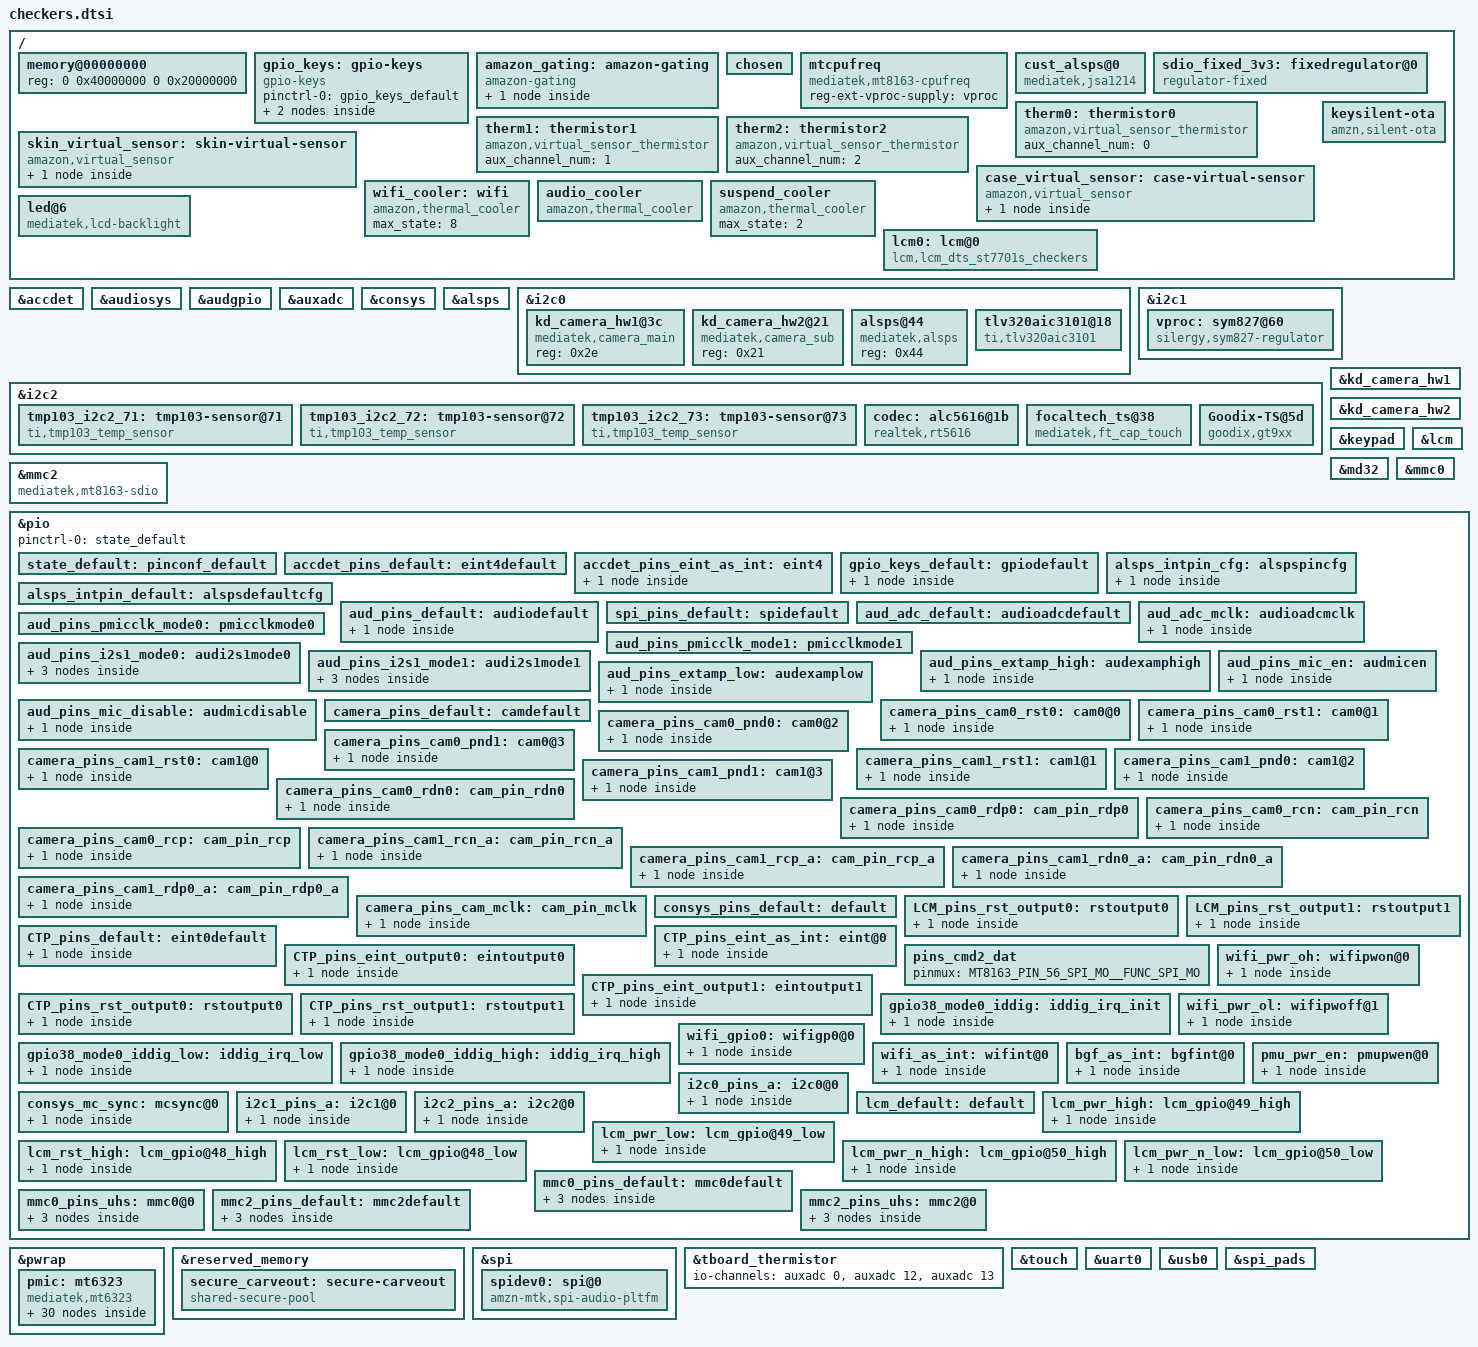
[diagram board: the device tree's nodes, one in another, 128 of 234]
/*
 * Copyright (C) 2018 Amazon.com
 *
 * This program is free software: you can redistribute it and/or modify
 * it under the terms of the GNU General Public License version 2 as
 * published by the Free Software Foundation.
 *
 * This program is distributed in the hope that it will be useful,
 * but WITHOUT ANY WARRANTY; without even the implied warranty of
 * MERCHANTABILITY or FITNESS FOR A PARTICULAR PURPOSE. See the
 * GNU General Public License for more details.
 *
 */

#include "mt8163.dtsi"
#include <dt-bindings/gpio/gpio.h>

/ {
	memory@00000000 {
		device_type = "memory";
		reg = <0 0x40000000 0 0x20000000>;
	};

	gpio_keys: gpio-keys {
		compatible = "gpio-keys";
		pinctrl-names = "default";
		pinctrl-0 = <&gpio_keys_default>;

		button@0 {
			debounce_interval = <50>;
			wakeup-source;
			gpio-key,wakeup = <1>;
			gpios = <&pio 36 1>;
			label = "volumeup";
			linux,input-type = <0x1>;
			linux,code = <115>;
		};

		button@1 {
			debounce_interval = <50>;
			wakeup-source;
			gpio-key,wakeup = <1>;
			gpios = <&pio 37 1>;
			label = "volumedown";
			linux,input-type = <0x1>;
			linux,code = <114>;
		};
	};

	amazon_gating: amazon-gating {
		compatible = "amazon-gating";
		state-gpios = <&pio 48 GPIO_ACTIVE_LOW>;
		enable-gpios = <&pio 27 GPIO_ACTIVE_HIGH>;
		status="okay";

		input_event {
			label = "mute";
			linux,code = <116>;
			debounce-interval = <50>;
			wakeup-source;
			gpios = <&pio 47 GPIO_ACTIVE_HIGH>;
		};
	};

	chosen {
		bootargs = "console=ttyMT0,921600n1 root=/dev/ram initrd=0x44000200,0x200000";
	};

	mtcpufreq {
		compatible = "mediatek,mt8163-cpufreq";
		reg-ext-vproc-supply = <&vproc>;
	};

	cust_alsps@0 {
		compatible = "mediatek,jsa1214";
		i2c_num = <0>;
		i2c_addr = <0x44>;
		polling_mode_ps = <0>;
		polling_mode_als = <1>;
		power_id = <0xffff>;
		power_vol  = <0>;
		als_level = <0 257 637 1027 2297 5588 6730 11301 20449 25768 31122 45552 57937 57937 57937>;
		als_value = <0 132 304 502 1004 2003 3006 5006 8004 10000 12000 16000 20000 20000 20000 20000>;
		ps_threshold_high = <70>;
		ps_threshold_low = <40>;
		is_batch_supported_ps = <1>;
	};

	sdio_fixed_3v3: fixedregulator@0 {
		compatible = "regulator-fixed";
		regulator-name = "sdio_fixed_3v3";
		regulator-min-microvolt = <3300000>;
		regulator-max-microvolt = <3300000>;
		gpio = <&pio 32 GPIO_ACTIVE_HIGH>;
		enable-active-high;
		startup-delay-us = <500000>;
	};

	therm0: thermistor0 {
		compatible = "amazon,virtual_sensor_thermistor";
		#thermal-sensor-cells = <0>;
		aux_channel_num = <0>;
	};
	therm1: thermistor1 {
		compatible = "amazon,virtual_sensor_thermistor";
		#thermal-sensor-cells = <0>;
		aux_channel_num = <1>;
	};
	therm2: thermistor2 {
		compatible = "amazon,virtual_sensor_thermistor";
		#thermal-sensor-cells = <0>;
		aux_channel_num = <2>;
	};

	skin_virtual_sensor: skin-virtual-sensor {
		compatible = "amazon,virtual_sensor";
		#thermal-sensor-cells = <0>;

		zone-list {
			zone-names = "therm0_s", "therm1_s", "therm2_s", "mtktscpu";
			therm0_s = <0 10000 100 550 (-40000) 125000>;
			therm1_s = <0 26949 100 100 (-40000) 125000>;
			therm2_s = <0 0 0 0 (-40000) 125000>;
			mtktscpu = <0 0 0 0 0 0>;
		};
	};

	case_virtual_sensor: case-virtual-sensor {
		compatible = "amazon,virtual_sensor";
		#thermal-sensor-cells = <0>;

		zone-list {
			zone-names = "therm0_s", "therm1_s", "therm2_s", "mtktscpu";
			therm0_s = <0 0 0 0 (-40000) 125000>;
			therm1_s = <0 0 0 0 (-40000) 125000>;
			therm2_s = <0 0 0 0 (-40000) 125000>;
			mtktscpu = <0 0 100 1000 0 0>;
		};
	};

	wifi_cooler: wifi {
		compatible = "amazon,thermal_cooler";
		#cooling-cells = <2>;
		max_state = <8>;
	};

	audio_cooler: audio_cooler {
		compatible = "amazon,thermal_cooler";
		#cooling-cells = <2>;
		max_level = <3>;
		max_state = <8>;
	};

	suspend_cooler: suspend_cooler {
		compatible = "amazon,thermal_cooler";
		#cooling-cells = <2>;
		max_state = <2>;
	};

	led@6 {
		compatible = "mediatek,lcd-backlight";
		led_mode = <5>;
		data = < >;
		pwm_config = <0 0 0 0 0>;
		gpios = <&pio 59 0>;
	};

	lcm0: lcm@0{
		compatible = "lcm,lcm_dts_st7701s_checkers";
		pinctrl-names = "default";
		lcm_auxadc_channel = <0>;
		lcm_reset_gpio = <&pio 83 0>;
		lcm-vio-supply = <&mt6323_vgp3_reg>;
		lcm-vgp-supply = <&mt6323_vio28_reg>;
		status = "okay";
	};

	keysilent-ota {
		compatible = "amzn,silent-ota";
		keys_down = "KEY_POWER";
		keys_down_delay = <0>;
		status = "okay";
	};
};

&accdet {
	interrupt-parent = <&pio>;
	interrupts = <4 IRQ_TYPE_LEVEL_LOW>;
	eint-debounce = <256000>;
	accdet-gpio = <&pio 26 0>;
	mic_dangling_vol = <1650>;
	mic_voltage_delay = <80>;
	switch-mode-vol = <550>;
	switch-mode-delay = <500>;
	accdet-mic-vol = <7>;
	headset-mode-setting = <0x500 0x500 1 0x1f0 0x800 0x800 0x4000>;
	accdet-plugout-debounce = <1000>;
	accdet-mic-mode = <1>;
	accdet-micbias1-ind-ctl = <1>;
	headset-three-key-threshold = <0 100 220 500>;
	headset-four-key-threshold = <0 58 121 192 450>;
	pinctrl-names = "default", "state_eint_as_int";
	pinctrl-0 = <&accdet_pins_default>;
	pinctrl-1 = <&accdet_pins_eint_as_int>;
	status = "okay";
};

&audiosys {
	/*0:Stereo, 1:MonoLeft, 2:MonoRight*/
	channel-type = <0>;
	switch-mode-delay = <1>;
	sound-dai = <&codec>;
	/* MCLK Frequency for ADC/DAC */
	mclk-frequency = <24576000>;
	/* enable mic callback for gating mode */
	gating_mode_callback_en = <1>;
	/* enable mclk source for DAC clock, 0 for Bclk */
	use_mclk_source_en = <0>;
};

&audgpio {
	pinctrl-names = "default",
			"audpmicclk-mode0",
			"audpmicclk-mode1",
			"audi2s1-mode0",
			"audi2s1-mode1",
			"extamp-pullhigh",
			"extamp-pulllow",
			"i2s-mclk",
			"mic-enable",
			"mic-disable";
	pinctrl-0 = <&aud_pins_default>;
	pinctrl-1 = <&aud_pins_pmicclk_mode0>;
	pinctrl-2 = <&aud_pins_pmicclk_mode1>;
	pinctrl-3 = <&aud_pins_i2s1_mode0>;
	pinctrl-4 = <&aud_pins_i2s1_mode1>;
	pinctrl-5 = <&aud_pins_extamp_high>;
	pinctrl-6 = <&aud_pins_extamp_low>;
	pinctrl-7 = <&aud_adc_mclk>;
	pinctrl-8 = <&aud_pins_mic_en>;
	pinctrl-9 = <&aud_pins_mic_disable>;

	clocks = <&infracfg CLK_INFRA_AUDIO>,
			<&topckgen CLK_TOP_AUDIO_SEL>,
			<&topckgen CLK_TOP_AUD_INTBUS_SEL>,
			<&topckgen CLK_TOP_AUD_1_SEL>,
			<&topckgen CLK_TOP_AUD_2_SEL>,
			<&topckgen CLK_TOP_APLL1>,
			<&topckgen CLK_TOP_APLL2>,
			<&audiosys CLK_AUDIO_AFE>,
			<&audiosys CLK_AUDIO_DAC>,
			<&audiosys CLK_AUDIO_DAC_PREDIS>,
			<&audiosys CLK_AUDIO_ADC>,
			<&audiosys CLK_AUDIO_22M>,
			<&audiosys CLK_AUDIO_24M>,
			<&audiosys CLK_AUDIO_I2S>,
			<&audiosys CLK_AUDIO_APLL_TUNER>,
			<&audiosys CLK_AUDIO_APLL2_TUNER>,
			<&clk26m>;

	clock-names = "aud_infra_clk",
			"top_mux_audio",
			"top_mux_audio_intbus",
			"aud_mux1_clk",
			"aud_mux2_clk",
			"apll1_clk",
			"apll2_clk",
			"aud_afe",
			"aud_dac",
			"aud_dac_predis",
			"aud_adc",
			"aud_22m",
			"aud_24m",
			"aud_i2s",
			"aud_apll_tnr",
			"aud_apll2_tnr",
			"top_clk26m_clk";

	status = "okay";
};

&auxadc {
	status = "okay";
};

&consys {
	pinctrl-names = "default",
			"wifi_pwr_on",
			"wifi_pwr_off",
			"wifi_gpio0",
			"wifi_int",
			"bgf_int",
			"pmu_pw_en",
			"mc_sync";
	pinctrl-0 = <&consys_pins_default>;
	pinctrl-1 = <&wifi_pwr_oh>;
	pinctrl-2 = <&wifi_pwr_ol>;
	pinctrl-3 = <&wifi_gpio0>;
	pinctrl-4 = <&wifi_as_int>;
	pinctrl-5 = <&bgf_as_int>;
	pinctrl-6 = <&pmu_pwr_en>;
	pinctrl-7 = <&consys_mc_sync>;
	vio18-supply = <&mt6323_vio18_reg>;
	status = "okay";
};

&alsps {
	pinctrl-names = "pin_default", "pin_cfg";
	pinctrl-0 = <&alsps_intpin_default>;
	pinctrl-1 = <&alsps_intpin_cfg>;
	vcn28-supply = <&mt6323_vcn28_reg>;
	status = "okay";
};

&i2c0 {
	clock-frequency = <400000>;
	pinctrl-names = "default";
	pinctrl-0 = <&i2c0_pins_a>;
	status = "okay";

	kd_camera_hw1@3c {
		compatible = "mediatek,camera_main";
		reg = <0x2e>;
	};

	kd_camera_hw2@21 {
		compatible = "mediatek,camera_sub";
		reg = <0x21>;
	};

	alsps@44 {
		compatible = "mediatek,alsps";
		reg = <0x44>;
		status = "okay";
	};

	tlv320aic3101@18 {
		compatible = "ti,tlv320aic3101";
		reg = <0x18>;
		enable-gpio = <&pio 24 0>;
		clocks = <&clk26m>;
		clock-names = "mclk";
	};
};

&i2c1 {
	clock-frequency = <400000>;
	pinctrl-names = "default";
	pinctrl-0 = <&i2c1_pins_a>;
	status = "okay";

	vproc: sym827@60 {
		compatible = "silergy,sym827-regulator";
		reg = <0x60>;
		regulator-name = "vproc";
		regulator-min-microvolt = <600000>;
		regulator-max-microvolt = <1387500>;
		regulator-enable-ramp-delay = <400>;
		regulator-ramp-delay = <8333>;
		regulator-always-on;
		vsel-gpio = <&pio 34 0>;
	};
};

&i2c2 {
	clock-frequency = <400000>;
	pinctrl-names = "default";
	pinctrl-0 = <&i2c2_pins_a>;
	status = "okay";

	tmp103_i2c2_71: tmp103-sensor@71 {
		compatible = "ti,tmp103_temp_sensor";
		reg = <0x71>;
		tmp103-sensor,offset = <2300>;
		tmp103-sensor,alpha = <10>;
		tmp103-sensor,weight = <0>;
	};
	tmp103_i2c2_72: tmp103-sensor@72 {
		compatible = "ti,tmp103_temp_sensor";
		reg = <0x72>;
		tmp103-sensor,offset = <750>;
		tmp103-sensor,alpha = <10>;
		tmp103-sensor,weight = <0>;
	};
	tmp103_i2c2_73: tmp103-sensor@73 {
		compatible = "ti,tmp103_temp_sensor";
		reg = <0x73>;
		tmp103-sensor,offset = <750>;
		tmp103-sensor,alpha = <10>;
		tmp103-sensor,weight = <0>;
	};

	codec: alc5616@1b {
		compatible = "realtek,rt5616";
		reg = <0x1b>;
		/* hw_mode=1 for differential 0 for Single_end*/
		hw_mode= <1>;
		/* Checkers Buzz and Pop SW solution */
		depop_mode= <1>;
		realtek,amp-gpio = <&pio 35 0>;
		pinctrl-names = "default",
				"adc-mclk";
		pinctrl-0 = <&aud_adc_default>;
		pinctrl-1 = <&aud_adc_mclk>;
	};

	focaltech_ts@38{
		compatible = "mediatek,ft_cap_touch";
		reg = <0x38>;
		vdd-supply = <&mt6323_vmch_reg>;
		vccio-supply = <&mt6323_vio18_reg>;
		focaltech,rst-gpio = <&pio 123 0x00>;
		focaltech,irq-gpio = <&pio 122 0x00>;
		focaltech,display-data = <0 480 0 960>;
		focaltech,fts-key-number = <5>;
	};

	Goodix-TS@5d{
		compatible = "goodix,gt9xx";
		reg = <0x5d>;
		goodix,rst-gpio = <&pio 123 0x00>;
		goodix,irq-gpio = <&pio 122 0x00>;
		vdd_ana-supply = <&mt6323_vmch_reg>;
		/* for now, we'd better not control VIO18 as it is shared by other circuits */
		/* vcc_i2c-supply = <&mt6323_vio18_reg>; */
		/* KD module config */
		goodix,cfg-group0 = [
		51 E0 01 C0 03 05 35 08 01 08
		23 05 50 32 25 03 00 00 00 00
		22 02 30 14 1B 1F 14 8C EC 0C
		50 52 7C 06 46 41 61 BB 02 10
		00 00 00 00 00 00 00 00 00 00
		00 3C 58 8F E0 65 14 0A 00 04
		9A 3E 00 91 43 00 8A 48 00 82
		4E 00 7B 54 00 7B 00 00 00 00
		01 1E 14 00 00 00 00 50 7C 06
		1E 00 00 00 00 00 00 00 00 00
		00 00 00 00 00 00 00 00 00 00
		00 00 18 16 14 12 10 0E 0C 0A
		08 06 04 02 FF FF FF FF FF FF
		FF FF FF FF FF FF FF FF FF FF
		FF FF 00 02 04 06 08 0A 0C 0F
		10 12 13 14 16 18 1C 1D 1E 1F
		20 21 22 24 26 28 FF FF FF FF
		FF FF FF FF FF FF FF FF FF FF
		FF FF FF FF 23 01];
		/* TRULY module config */
		goodix,cfg-group1 = [
		51 E0 01 C0 03 05 35 08 01 08
		23 05 50 32 25 03 00 00 00 00
		22 02 30 14 1B 1F 14 8C EC 0C
		50 52 7C 06 46 41 61 BB 02 10
		00 00 00 00 00 00 00 00 00 00
		00 3C 58 8F E0 65 14 0A 00 04
		9A 3E 00 91 43 00 8A 48 00 82
		4E 00 7B 54 00 7B 00 00 00 00
		01 1E 14 00 00 00 00 50 7C 06
		1E 00 00 00 00 00 00 00 00 00
		00 00 00 00 00 00 00 00 00 00
		00 00 18 16 14 12 10 0E 0C 0A
		08 06 04 02 FF FF FF FF FF FF
		FF FF FF FF FF FF FF FF FF FF
		FF FF 00 02 04 06 08 0A 0C 0F
		10 12 13 14 16 18 1C 1D 1E 1F
		20 21 22 24 26 28 FF FF FF FF
		FF FF FF FF FF FF FF FF FF FF
		FF FF FF FF 23 01];
		/* INX module config */
		goodix,cfg-group2 = [
		51 E0 01 C0 03 05 35 08 01 08
		23 05 50 32 25 03 00 00 00 00
		22 02 30 14 1B 1F 14 8C EC 0C
		50 52 7C 06 46 41 61 BB 02 10
		00 00 00 00 00 00 00 00 00 00
		00 3C 58 8F E0 65 14 0A 00 04
		9A 3E 00 91 43 00 8A 48 00 82
		4E 00 7B 54 00 7B 00 00 00 00
		01 1E 14 00 00 00 00 50 7C 06
		1E 00 00 00 00 00 00 00 00 00
		00 00 00 00 00 00 00 00 00 00
		00 00 18 16 14 12 10 0E 0C 0A
		08 06 04 02 FF FF FF FF FF FF
		FF FF FF FF FF FF FF FF FF FF
		FF FF 00 02 04 06 08 0A 0C 0F
		10 13 12 14 16 18 1C 1D 1E 1F
		20 26 28 21 22 24 FF FF FF FF
		FF FF FF FF FF FF FF FF FF FF
		FF FF FF FF 23 01];
		/* KD_WALLY module config */
		goodix,cfg-group3 = [
		51 E0 01 C0 03 05 35 08 01 08
		23 05 50 32 25 03 00 00 00 00
		22 02 30 14 1B 1F 14 8C EC 0C
		50 52 7C 06 46 41 61 BB 02 10
		00 00 00 00 00 00 00 00 00 00
		00 3C 58 8F E0 65 14 0A 00 04
		9A 3E 00 91 43 00 8A 48 00 82
		4E 00 7B 54 00 7B 00 00 00 00
		01 1E 14 00 00 00 00 50 7C 06
		1E 00 00 00 00 00 00 00 00 00
		00 00 00 00 00 00 00 00 00 00
		00 00 18 16 14 12 10 0E 0C 0A
		08 06 04 02 FF FF FF FF FF FF
		FF FF FF FF FF FF FF FF FF FF
		FF FF 00 02 04 06 08 0A 0C 0F
		10 12 13 14 16 18 1C 1D 1E 1F
		20 21 22 24 26 28 FF FF FF FF
		FF FF FF FF FF FF FF FF FF FF
		FF FF FF FF 23 01];
		status = "okay";
	};
};

/* Main Cam */
&kd_camera_hw1 {

	reg-vcama-supply = <&mt6323_vcama_reg>;
	reg-vcamd-supply = <&mt6323_vgp1_reg>;
	reg-vcamio-supply = <&mt6323_vcamio_reg>;
	reg-vcami2c-supply = <&mt6323_vio18_reg>;	/*I2C*/

	pinctrl-names = "default", "cam_mclk",
		"cam0_rst0", "cam0_rst1", "cam0_pnd0", "cam0_pnd1",
		"cam0_rdn0", "cam0_rdp0", "cam0_rcn", "cam0_rcp";
	pinctrl-0 = <&camera_pins_default>;
	pinctrl-1 = <&camera_pins_cam_mclk>;
	pinctrl-2 = <&camera_pins_cam0_rst0>;
	pinctrl-3 = <&camera_pins_cam0_rst1>;
	pinctrl-4 = <&camera_pins_cam0_pnd0>;
	pinctrl-5 = <&camera_pins_cam0_pnd1>;
	pinctrl-6 = <&camera_pins_cam0_rdn0>;
	pinctrl-7 = <&camera_pins_cam0_rdp0>;
	pinctrl-8 = <&camera_pins_cam0_rcn>;
	pinctrl-9 = <&camera_pins_cam0_rcp>;
	status = "okay";

};

/* Sub Cam */
/* FIX ME: same power pins as Main ? */
&kd_camera_hw2 {
	reg-vcama-supply = <&mt6323_vcama_reg>;
	reg-vcamd-supply = <&mt6323_vgp1_reg>;
	reg-vcamio-supply = <&mt6323_vcamio_reg>;
	reg-vcami2c-supply = <&mt6323_vio18_reg>;	/*I2C*/
};

&keypad {
};

&lcm {
	pinctrl-names = "default";
	lcm_reset_gpio = <&pio 83 0>;
	reg-lcm-supply = <&mt6323_vgp3_reg>;
	reg-lcm-supply1 = <&mt6323_vio28_reg>;
};

&md32 {
	status = "okay";
};

&mmc0 {
	pinctrl-names = "default", "state_uhs";
	pinctrl-0 = <&mmc0_pins_default>;
	pinctrl-1 = <&mmc0_pins_uhs>;
	status = "okay";
	bus-width = <8>;
	mediatek,latch-ck = <1>;
	max-frequency = <200000000>;
	/*cap-mmc-highspeed;*/
	mmc-hs200-1_8v;
	cap-mmc-hw-reset;
	vmmc-supply = <&mt6323_vemc3v3_reg>;
	vqmmc-supply = <&mt6323_vio18_reg>;
	non-removable;
};

&mmc2 {
	compatible = "mediatek,mt8163-sdio";
	pinctrl-names = "default", "state_uhs";
	pinctrl-0 = <&mmc2_pins_default>;
	pinctrl-1 = <&mmc2_pins_uhs>;
	status = "okay";
	bus-width = <4>;
	max-frequency = <200000000>;
	sd-uhs-sdr104;
	cap-sd-highspeed;
	keep-power-in-suspend;
	enable-sdio-wakeup;
	vmmc-supply = <&sdio_fixed_3v3>;
	cap-sdio-irq;
	non-removable;
	mt76x8_pmu_en_gpio = <&pio 32 0>;
	mt76x8_pmu_en_delay = <5>; /* ms */
};

&pio {
	pinctrl-names = "default";
	pinctrl-0 = <&state_default>;

	state_default:pinconf_default {
	};

	accdet_pins_default: eint4default {
	};

	accdet_pins_eint_as_int: eint4 {
		pins_cmd_dat {
			pinmux = <MT8163_PIN_26_EINT4__FUNC_GPIO26>;
			bias-disable;
		};
	};

	gpio_keys_default: gpiodefault {
		pins_cmd_dat {
			pinmux = <MT8163_PIN_36_KPCOL0__FUNC_GPIO36>,
			<MT8163_PIN_37_KPCOL1__FUNC_GPIO37>;
			slew-rate = <0>;
			bias-pull-up = <MTK_PUPD_SET_R1R0_01>;
			input-enable;
		};
	};

	alsps_intpin_cfg: alspspincfg {
		pins_cmd_dat {
			pinmux = <MT8163_PIN_52_EINT20__FUNC_GPIO52>;
			slew-rate = <0>;
			bias-pull-up = <00>;
		};
	};

	alsps_intpin_default: alspsdefaultcfg {
	};

	aud_pins_default: audiodefault {
		pins1 {
			pinmux = <MT8163_PIN_18_PCM_CLK__FUNC_I2S0_BCK0>,
				<MT8163_PIN_19_PCM_SYNC__FUNC_I2S0_LRCK>,
				<MT8163_PIN_20_PCM_RX__FUNC_I2S0_DI>,
				<MT8163_PIN_21_PCM_TX__FUNC_I2S3_DO>;
		};
	};

	spi_pins_default: spidefault {
	};

	aud_adc_default: audioadcdefault {
	};

	aud_adc_mclk: audioadcmclk {
		pins_cmd_dat {
			pinmux = <MT8163_PIN_6_PWRAP_SPI0_CSN2__FUNC_I2S1_MCK>;
		};
	};

	aud_pins_pmicclk_mode0: pmicclkmode0 {
	};

	aud_pins_pmicclk_mode1: pmicclkmode1 {
	};

	aud_pins_i2s1_mode0: audi2s1mode0 {
		pins_cmd0_dat {
			pinmux = <MT8163_PIN_72_I2S_DATA_IN__FUNC_GPIO72>;
		};
		pins_cmd1_dat {
			pinmux = <MT8163_PIN_73_I2S_LRCK__FUNC_GPIO73>;
		};
		pins_cmd2_dat {
			pinmux = <MT8163_PIN_74_I2S_BCK__FUNC_GPIO74>;
		};
	};

	aud_pins_i2s1_mode1: audi2s1mode1 {
		pins_cmd0_dat {
			pinmux = <MT8163_PIN_72_I2S_DATA_IN__FUNC_I2S1_DO>;
			drive-strength = <MTK_DRIVE_8mA>;
		};
		pins_cmd1_dat {
			pinmux = <MT8163_PIN_73_I2S_LRCK__FUNC_I2S1_LRCK>;
			drive-strength = <MTK_DRIVE_8mA>;
		};
		pins_cmd2_dat {
			pinmux = <MT8163_PIN_74_I2S_BCK__FUNC_I2S1_BCK>;
			drive-strength = <MTK_DRIVE_8mA>;
		};
	};

	aud_pins_extamp_high: audexamphigh {
		pins_cmd_dat {
			pinmux = <MT8163_PIN_35_KPROW2__FUNC_GPIO35>;
			slew-rate = <1>;
			output-high;
		};
	};

	aud_pins_extamp_low: audexamplow {
		pins_cmd_dat {
			pinmux = <MT8163_PIN_35_KPROW2__FUNC_GPIO35>;
			slew-rate = <1>;
			output-low;
		};
	};

	aud_pins_mic_en: audmicen {
		pins_cmd0_dat {
			pinmux = <MT8163_PIN_46_EINT14__FUNC_GPIO46>;
			slew-rate = <1>;
			output-high;
		};
	};

	aud_pins_mic_disable: audmicdisable {
		pins_cmd0_dat {
			pinmux = <MT8163_PIN_46_EINT14__FUNC_GPIO46>;
			slew-rate = <1>;
			output-low;
		};
	};

	camera_pins_default: camdefault {
	};

	camera_pins_cam0_rst0: cam0@0 {
		pins_cmd_dat {
			pinmux = <MT8163_PIN_22_EINT0__FUNC_GPIO22>;/* GPIO_CAMERA_CMRST_PIN */
			slew-rate = <1>; /* direction 0:in, 1:out */
			output-low;/* direction out used only. output_low or high */
		};
	};

	camera_pins_cam0_rst1: cam0@1 {
		pins_cmd_dat {
			pinmux = <MT8163_PIN_22_EINT0__FUNC_GPIO22>;/* GPIO_CAMERA_CMRST_PIN */
			slew-rate = <1>;
			output-high;
		};
	};

	camera_pins_cam0_pnd0: cam0@2 {
		pins_cmd_dat {
			pinmux = <MT8163_PIN_23_EINT1__FUNC_GPIO23>;/* GPIO_CAMERA_CMPDN_PIN */
			slew-rate = <1>;
			output-low;
		};
	};

	camera_pins_cam0_pnd1: cam0@3 {
		pins_cmd_dat {
			pinmux = <MT8163_PIN_23_EINT1__FUNC_GPIO23>;/* GPIO_CAMERA_CMPDN_PIN */
			slew-rate = <1>;
			output-high;
		};
	};

	camera_pins_cam1_rst0: cam1@0 {
		pins_cmd_dat {
			pinmux = <MT8163_PIN_22_EINT0__FUNC_GPIO22>;/* GPIO_CAMERA_CMRST1_PIN */
			slew-rate = <1>; /* direction 0:in, 1:out */
			output-low;/* direction out used only. output_low or high */
		};
	};

	camera_pins_cam1_rst1: cam1@1 {
		pins_cmd_dat {
			pinmux = <MT8163_PIN_22_EINT0__FUNC_GPIO22>;/* GPIO_CAMERA_CMRST1_PIN */
			slew-rate = <1>;
			output-high;
		};
	};

	camera_pins_cam1_pnd0: cam1@2 {
		pins_cmd_dat {
			pinmux = <MT8163_PIN_23_EINT1__FUNC_GPIO23>;/* GPIO_CAMERA_CMPDN1_PIN */
			slew-rate = <1>;
			output-low;
		};
	};

	camera_pins_cam1_pnd1: cam1@3 {
		pins_cmd_dat {
			pinmux = <MT8163_PIN_23_EINT1__FUNC_GPIO23>;/* GPIO_CAMERA_CMPDN1_PIN */
			slew-rate = <1>;
			output-high;
		};
	};

	camera_pins_cam0_rdn0: cam_pin_rdn0 {
		pins_cmd_dat {
			pinmux = <MT8163_PIN_101_RDN0__FUNC_RDN0>;
		};
	};

	camera_pins_cam0_rdp0: cam_pin_rdp0 {
		pins_cmd_dat {
			pinmux = <MT8163_PIN_102_RDP0__FUNC_RDP0>;
		};
	};

	camera_pins_cam0_rcn: cam_pin_rcn {
		pins_cmd_dat {
			pinmux = <MT8163_PIN_105_RCN__FUNC_RCN>;
		};
	};

	camera_pins_cam0_rcp: cam_pin_rcp {
		pins_cmd_dat {
			pinmux = <MT8163_PIN_106_RCP__FUNC_RCP>;
		};
	};

	camera_pins_cam1_rcn_a: cam_pin_rcn_a {
		pins_cmd_dat {
			pinmux = <MT8163_PIN_111_RCN_A__FUNC_RCN_A>;
		};
	};

	camera_pins_cam1_rcp_a: cam_pin_rcp_a {
		pins_cmd_dat {
			pinmux = <MT8163_PIN_112_RCP_A__FUNC_RCP_A>;
		};
	};

	camera_pins_cam1_rdn0_a: cam_pin_rdn0_a {
		pins_cmd_dat {
			pinmux = <MT8163_PIN_115_RDN0_A__FUNC_RDN0_A>;
		};
	};

	camera_pins_cam1_rdp0_a: cam_pin_rdp0_a {
		pins_cmd_dat {
			pinmux = <MT8163_PIN_116_RDP0_A__FUNC_RDP0_A>;
		};
	};

	camera_pins_cam_mclk: cam_pin_mclk {
		pins_cmd_dat {
			pinmux = <MT8163_PIN_119_CMMCLK__FUNC_CMMCLK>;
		};
	};

	consys_pins_default: default {

	};

	LCM_pins_rst_output0: rstoutput0 {
		pins_cmd_dat {
		pinmux = <MT8163_PIN_83_LCM_RST__FUNC_GPIO83>;
			slew-rate = <1>;
			output-low;
		};
	};

	LCM_pins_rst_output1: rstoutput1 {
		pins_cmd_dat {
			pinmux = <MT8163_PIN_83_LCM_RST__FUNC_GPIO83>;
			slew-rate = <1>;
			output-high;
		};
	};

	CTP_pins_default: eint0default {
		pins_cmd_dat {
			pinmux = <MT8163_PIN_122_MSDC1_CLK__FUNC_GPIO122>;
			slew-rate = <0>;
			bias-disable;
		};
	};

	CTP_pins_eint_as_int: eint@0 {
		pins_cmd_dat {
			pinmux = <MT8163_PIN_122_MSDC1_CLK__FUNC_GPIO122>;
			slew-rate = <0>;
			bias-disable;
		};
	};

	CTP_pins_eint_output0: eintoutput0 {
		pins_cmd_dat {
			pinmux = <MT8163_PIN_122_MSDC1_CLK__FUNC_GPIO122>;
			slew-rate = <1>;
			output-low;
		};
	};
		pins_cmd2_dat {
			pinmux = <MT8163_PIN_56_SPI_MO__FUNC_SPI_MO>;
		};

	CTP_pins_eint_output1: eintoutput1 {
		pins_cmd_dat {
			pinmux = <MT8163_PIN_122_MSDC1_CLK__FUNC_GPIO122>;
			slew-rate = <1>;
			output-high;
		};
	};

	CTP_pins_rst_output0: rstoutput0 {
		pins_cmd_dat {
			pinmux = <MT8163_PIN_123_MSDC1_DAT0__FUNC_GPIO123>;
			slew-rate = <1>;
			output-low;
		};
	};

	CTP_pins_rst_output1: rstoutput1 {
		pins_cmd_dat {
			pinmux = <MT8163_PIN_123_MSDC1_DAT0__FUNC_GPIO123>;
			slew-rate = <1>;
			output-high;
		};
	};

	gpio38_mode0_iddig: iddig_irq_init {
		pins_cmd_dat {
			pinmux = <MT8163_PIN_38_KPCOL2__FUNC_GPIO38>;
			bias-pull-up;
		};
	};

	gpio38_mode0_iddig_low: iddig_irq_low {
		pins_cmd_dat {
			pinmux = <MT8163_PIN_38_KPCOL2__FUNC_GPIO38>;
			bias-pull-down;
		};
	};

	gpio38_mode0_iddig_high: iddig_irq_high {
		pins_cmd_dat {
			pinmux = <MT8163_PIN_38_KPCOL2__FUNC_GPIO38>;
			bias-pull-up;
		};
	};

	wifi_pwr_oh: wifipwon@0 {
		pins_cmd_dat {
			pinmux = <MT8163_PIN_28_EINT6__FUNC_GPIO28>;
			slew-rate = <1>;
			output-high;
		};
	};

	wifi_pwr_ol: wifipwoff@1 {
		pins_cmd_dat {
			pinmux = <MT8163_PIN_28_EINT6__FUNC_GPIO28>;
			slew-rate = <1>;
			output-low;
		};
	};

	wifi_gpio0: wifigp0@0 {
		pins_cmd_dat {
			pinmux = <MT8163_PIN_29_EINT7__FUNC_GPIO29>;
			slew-rate = <1>;
			output-low;
		};
	};

	wifi_as_int: wifint@0 {
		pins_cmd_dat {
			pinmux = <MT8163_PIN_30_EINT8__FUNC_GPIO30>;
			slew-rate = <0>;
			bias-disable;
		};
	};

	bgf_as_int: bgfint@0 {
		pins_cmd_dat {
			pinmux = <MT8163_PIN_31_EINT9__FUNC_GPIO31>;
			slew-rate = <0>;
			bias-disable;
		};
	};

	pmu_pwr_en: pmupwen@0 {
		pins_cmd_dat {
			pinmux = <MT8163_PIN_32_EINT10__FUNC_GPIO32>;
			slew-rate = <1>;
			output-low;
		};
	};

	consys_mc_sync: mcsync@0 {
		pins_cmd_dat {
			pinmux = <MT8163_PIN_33_KPROW0__FUNC_GPIO33>;
			slew-rate = <1>;
			output-low;
		};
	};

	i2c0_pins_a: i2c0@0 {
		pins1 {
			pinmux = <MT8163_PIN_75_SDA0__FUNC_SDA0_0>,
				 <MT8163_PIN_76_SCL0__FUNC_SCL0_0>;
			bias-disable;
		};
	};

	i2c1_pins_a: i2c1@0 {
		pins1 {
			pinmux = <MT8163_PIN_57_SDA1__FUNC_SDA1_0>,
				 <MT8163_PIN_58_SCL1__FUNC_SCL1_0>;
			bias-disable;
		};
	};

	i2c2_pins_a: i2c2@0 {
		pins1 {
			pinmux = <MT8163_PIN_77_SDA2__FUNC_SDA2_0>,
				 <MT8163_PIN_78_SCL2__FUNC_SCL2_0>;
			bias-disable;
		};
	};

	lcm_default: default {
	};

	lcm_pwr_high: lcm_gpio@49_high {
		pins_cmd_dat {
			pinmux = <MT8163_PIN_49_EINT17__FUNC_GPIO49>;
			slew-rate = <1>;
			output-high;
		};
	};

	lcm_pwr_low: lcm_gpio@49_low {
		pins_cmd_dat {
			pinmux = <MT8163_PIN_49_EINT17__FUNC_GPIO49>;
			slew-rate = <1>;
			output-low;
		};
	};

	lcm_rst_high: lcm_gpio@48_high {
		pins_cmd_dat {
			pinmux = <MT8163_PIN_48_EINT16__FUNC_GPIO48>;
			slew-rate = <1>;
			output-high;
		};
	};

	lcm_rst_low: lcm_gpio@48_low {
		pins_cmd_dat {
			pinmux = <MT8163_PIN_48_EINT16__FUNC_GPIO48>;
			slew-rate = <1>;
			output-low;
		};
	};

	lcm_pwr_n_high: lcm_gpio@50_high {
		pins_cmd_dat {
			pinmux = <MT8163_PIN_50_EINT18__FUNC_GPIO50>;
			bias-disable;
		};
	};

	lcm_pwr_n_low: lcm_gpio@50_low {
		pins_cmd_dat {
			pinmux = <MT8163_PIN_50_EINT18__FUNC_GPIO50>;
			bias-disable;
		};
	};

	mmc0_pins_default: mmc0default {
		pins_cmd_dat {
			pinmux = <MT8163_PIN_137_MSDC0_DAT0__FUNC_MSDC0_DAT0>,
				<MT8163_PIN_136_MSDC0_DAT1__FUNC_MSDC0_DAT1>,
				<MT8163_PIN_135_MSDC0_DAT2__FUNC_MSDC0_DAT2>,
				<MT8163_PIN_134_MSDC0_DAT3__FUNC_MSDC0_DAT3>,
				<MT8163_PIN_130_MSDC0_DAT4__FUNC_MSDC0_DAT4>,
				<MT8163_PIN_129_MSDC0_DAT5__FUNC_MSDC0_DAT5>,
				<MT8163_PIN_128_MSDC0_DAT6__FUNC_MSDC0_DAT6>,
				<MT8163_PIN_127_MSDC0_DAT7__FUNC_MSDC0_DAT7>,
				<MT8163_PIN_132_MSDC0_CMD__FUNC_MSDC0_CMD>;
			input-enable;
			bias-pull-up;
		};

		pins_clk {
			pinmux = <MT8163_PIN_133_MSDC0_CLK__FUNC_MSDC0_CLK>;
			bias-pull-down;
		};

		pins_rst {
			pinmux = <MT8163_PIN_131_MSDC0_RSTB__FUNC_MSDC0_RSTB>;
			bias-pull-up;
		};
	};

	mmc0_pins_uhs: mmc0@0{
		pins_cmd_dat {
			pinmux = <MT8163_PIN_137_MSDC0_DAT0__FUNC_MSDC0_DAT0>,
				<MT8163_PIN_136_MSDC0_DAT1__FUNC_MSDC0_DAT1>,
				<MT8163_PIN_135_MSDC0_DAT2__FUNC_MSDC0_DAT2>,
				<MT8163_PIN_134_MSDC0_DAT3__FUNC_MSDC0_DAT3>,
				<MT8163_PIN_130_MSDC0_DAT4__FUNC_MSDC0_DAT4>,
				<MT8163_PIN_129_MSDC0_DAT5__FUNC_MSDC0_DAT5>,
				<MT8163_PIN_128_MSDC0_DAT6__FUNC_MSDC0_DAT6>,
				<MT8163_PIN_127_MSDC0_DAT7__FUNC_MSDC0_DAT7>,
				<MT8163_PIN_132_MSDC0_CMD__FUNC_MSDC0_CMD>;
			input-enable;
			drive-strength = <MTK_DRIVE_6mA>;
			bias-pull-up = <MTK_PUPD_SET_R1R0_01>;
		};

		pins_clk {
			pinmux = <MT8163_PIN_133_MSDC0_CLK__FUNC_MSDC0_CLK>;
			drive-strength = <MTK_DRIVE_6mA>;
			bias-pull-down = <MTK_PUPD_SET_R1R0_01>;
		};

		pins_rst {
			pinmux = <MT8163_PIN_131_MSDC0_RSTB__FUNC_MSDC0_RSTB>;
			bias-pull-up;
		};
	};

	mmc2_pins_default: mmc2default {
		pins_cmd_dat {
			pinmux = <MT8163_PIN_87_MSDC2_DAT0__FUNC_MSDC2_DAT0>,
				<MT8163_PIN_88_MSDC2_DAT1__FUNC_MSDC2_DAT1>,
				<MT8163_PIN_89_MSDC2_DAT2__FUNC_MSDC2_DAT2>,
				<MT8163_PIN_90_MSDC2_DAT3__FUNC_MSDC2_DAT3>,
				<MT8163_PIN_85_MSDC2_CMD__FUNC_MSDC2_CMD>;
			drive-strength = <MTK_DRIVE_6mA>;
			bias-pull-up = <MTK_PUPD_SET_R1R0_01>;
		};

		pins_clk {
			pinmux = <MT8163_PIN_86_MSDC2_CLK__FUNC_MSDC2_CLK>;
			drive-strength = <MTK_DRIVE_6mA>;
			bias-pull-down = <MTK_PUPD_SET_R1R0_10>;
		};

		pins_dev_power {
			pinmux = <MT8163_PIN_28_EINT6__FUNC_GPIO28>;
			output-low;
		};
	};

	mmc2_pins_uhs: mmc2@0 {
		pins_cmd_dat {
			pinmux = <MT8163_PIN_87_MSDC2_DAT0__FUNC_MSDC2_DAT0>,
				<MT8163_PIN_88_MSDC2_DAT1__FUNC_MSDC2_DAT1>,
				<MT8163_PIN_89_MSDC2_DAT2__FUNC_MSDC2_DAT2>,
				<MT8163_PIN_90_MSDC2_DAT3__FUNC_MSDC2_DAT3>,
				<MT8163_PIN_85_MSDC2_CMD__FUNC_MSDC2_CMD>;
			drive-strength = <MTK_DRIVE_8mA>;
			bias-pull-up = <MTK_PUPD_SET_R1R0_10>;
		};

		pins_clk {
			pinmux = <MT8163_PIN_86_MSDC2_CLK__FUNC_MSDC2_CLK>;
			drive-strength = <MTK_DRIVE_8mA>;
			bias-pull-down = <MTK_PUPD_SET_R1R0_10>;
		};

		pins_dev_power {
			pinmux = <MT8163_PIN_28_EINT6__FUNC_GPIO28>;
			output-high;
		};
	};
};

&pwrap {
	pmic: mt6323 {
		compatible = "mediatek,mt6323";

		pmicmt6323: pmicmt6323 {
			compatible = "mediatek,mt6323-pmic";
			interrupt-parent = <&pio>;
			interrupts = <24 IRQ_TYPE_LEVEL_HIGH>;
		};

		regulators {

			compatible = "mediatek,mt6323-regulator";

			mt6323_vproc_reg: buck_vproc {
				regulator-name = "vproc";
				regulator-min-microvolt = < 700000>;
				regulator-max-microvolt = <1350000>;
				regulator-ramp-delay = <12500>;
				regulator-always-on;
				regulator-boot-on;
			};

			mt6323_vsys_reg: buck_vsys {
				regulator-name = "vsys";
				regulator-min-microvolt = <1400000>;
				regulator-max-microvolt = <2987500>;
				regulator-ramp-delay = <25000>;
				regulator-always-on;
				regulator-boot-on;
			};

			mt6323_vpa_reg: buck_vpa {
				regulator-name = "vpa";
				regulator-min-microvolt = < 500000>;
				regulator-max-microvolt = <3650000>;
			};

			mt6323_vtcxo_reg: ldo_vtcxo {
				regulator-name = "vtcxo";
				regulator-min-microvolt = <2800000>;
				regulator-max-microvolt = <2800000>;
				regulator-enable-ramp-delay = <90>;
				regulator-always-on;
				regulator-boot-on;
			};

			mt6323_vcn28_reg: ldo_vcn28 {
				regulator-name = "vcn28";
				regulator-min-microvolt = <2800000>;
				regulator-max-microvolt = <2800000>;
				regulator-enable-ramp-delay = <185>;
			};

			mt6323_vcn33_bt_reg: ldo_vcn33_bt {
				regulator-name = "vcn33_bt";
				regulator-min-microvolt = <3300000>;
				regulator-max-microvolt = <3300000>;
				regulator-enable-ramp-delay = <185>;
				regulator-always-on;
				regulator-boot-on;
			};

			mt6323_vcn33_wifi_reg: ldo_vcn33_wifi {
				regulator-name = "vcn33_wifi";
				regulator-min-microvolt = <3300000>;
				regulator-max-microvolt = <3300000>;
				regulator-enable-ramp-delay = <185>;
				regulator-always-on;
				regulator-boot-on;
			};

			mt6323_va_reg: ldo_va {
				regulator-name = "va";
				regulator-min-microvolt = <2800000>;
				regulator-max-microvolt = <2800000>;
				regulator-enable-ramp-delay = <216>;
				regulator-always-on;
				regulator-boot-on;
			};

			mt6323_vcama_reg: ldo_vcama {
				regulator-name = "vcama";
				regulator-min-microvolt = <1500000>;
				regulator-max-microvolt = <2800000>;
				regulator-enable-ramp-delay = <216>;
			};

			mt6323_vio28_reg: ldo_vio28 {
				regulator-name = "vio28";
				regulator-min-microvolt = <2800000>;
				regulator-max-microvolt = <2800000>;
				regulator-enable-ramp-delay = <216>;
				regulator-boot-on;
			};

			mt6323_vusb_reg: ldo_vusb {
				regulator-name = "vusb";
				regulator-min-microvolt = <3300000>;
				regulator-max-microvolt = <3300000>;
				regulator-enable-ramp-delay = <216>;
				regulator-boot-on;
			};

			mt6323_vmc_reg: ldo_vmc {
				regulator-name = "vmc";
				regulator-min-microvolt = <1800000>;
				regulator-max-microvolt = <3300000>;
				regulator-enable-ramp-delay = <36>;
				regulator-boot-on;
			};

			mt6323_vmch_reg: ldo_vmch {
				regulator-name = "vmch";
				regulator-min-microvolt = <3000000>;
				regulator-max-microvolt = <3300000>;
				regulator-enable-ramp-delay = <36>;
				regulator-boot-on;
			};

			mt6323_vemc3v3_reg: ldo_vemc3v3 {
				regulator-name = "vemc3v3";
				regulator-min-microvolt = <3000000>;
				regulator-max-microvolt = <3300000>;
				regulator-enable-ramp-delay = <36>;
				regulator-boot-on;
			};

			mt6323_vgp1_reg: ldo_vgp1 {
				regulator-name = "vgp1";
				regulator-min-microvolt = <1200000>;
				regulator-max-microvolt = <3300000>;
				regulator-enable-ramp-delay = <216>;
			};

			mt6323_vgp2_reg: ldo_vgp2 {
				regulator-name = "vgp2";
				regulator-min-microvolt = <3000000>;
				regulator-max-microvolt = <3300000>;
				regulator-enable-ramp-delay = <216>;
				regulator-always-on;
				regulator-boot-on;
			};

			mt6323_vgp3_reg: ldo_vgp3 {
				regulator-name = "vgp3";
				regulator-min-microvolt = <1800000>;
				regulator-max-microvolt = <1800000>;
				regulator-boot-on;
				regulator-enable-ramp-delay = <216>;
			};

			mt6323_vcn18_reg: ldo_vcn18 {
				regulator-name = "vcn18";
				regulator-min-microvolt = <1800000>;
				regulator-max-microvolt = <1800000>;
				regulator-enable-ramp-delay = <216>;
			};

			mt6323_vsim1_reg: ldo_vsim1 {
				regulator-name = "vsim1";
				regulator-min-microvolt = <1800000>;
				regulator-max-microvolt = <3000000>;
				regulator-enable-ramp-delay = <216>;
				regulator-always-on;
				regulator-boot-on;
			};

			mt6323_vsim2_reg: ldo_vsim2 {
				regulator-name = "vsim2";
				regulator-min-microvolt = <1800000>;
				regulator-max-microvolt = <3000000>;
				regulator-enable-ramp-delay = <216>;
			};

			mt6323_vrtc_reg: ldo_vrtc {
				regulator-name = "vrtc";
				regulator-min-microvolt = <2800000>;
				regulator-max-microvolt = <2800000>;
				regulator-always-on;
				regulator-boot-on;
			};

			mt6323_vcamaf_reg: ldo_vcamaf {
				regulator-name = "vcamaf";
				regulator-min-microvolt = <1800000>;
				regulator-max-microvolt = <1800000>;
				regulator-enable-ramp-delay = <216>;
			};

			mt6323_vibr_reg: ldo_vibr {
				regulator-name = "vibr";
				regulator-min-microvolt = <3000000>;
				regulator-max-microvolt = <3000000>;
				regulator-enable-ramp-delay = <36>;
				regulator-always-on;
				regulator-boot-on;
			};

			mt6323_vrf18_reg: ldo_vrf18 {
				regulator-name = "vrf18";
				regulator-min-microvolt = <1825000>;
				regulator-max-microvolt = <1825000>;
				regulator-enable-ramp-delay = <187>;
				regulator-boot-on;
			};

			mt6323_vm_reg: ldo_vm {
				regulator-name = "vm";
				regulator-min-microvolt = <1200000>;
				regulator-max-microvolt = <1800000>;
				regulator-enable-ramp-delay = <216>;
				regulator-always-on;
				regulator-boot-on;
			};

			mt6323_vio18_reg: ldo_vio18 {
				regulator-name = "vio18";
				regulator-min-microvolt = <1800000>;
				regulator-max-microvolt = <1800000>;
				regulator-enable-ramp-delay = <216>;
				regulator-always-on;
				regulator-boot-on;
			};

			mt6323_vcamd_reg: ldo_vcamd {
				regulator-name = "vcamd";
				regulator-min-microvolt = <1200000>;
				regulator-max-microvolt = <1200000>;
				regulator-enable-ramp-delay = <216>;
				regulator-always-on;
				regulator-boot-on;
			};

			mt6323_vcamio_reg: ldo_vcamio {
				regulator-name = "vcamio";
				regulator-min-microvolt = <1800000>;
				regulator-max-microvolt = <1800000>;
				regulator-enable-ramp-delay = <216>;
			};
		};
	};
};

&reserved_memory {
	secure_carveout: secure-carveout {
		compatible = "shared-secure-pool";
		reusable;
		size = <0 0x4400000>;
		alignment = <0 0x400000>;
	};
};

&spi {
	status = "okay";
	spidev0: spi@0 {
		compatible = "amzn-mtk,spi-audio-pltfm";
		reg = <0>;
		spi-max-frequency = <100000000>;
		gpios = <&pio 51 0>;
		fpga-cdone-gpio = <&pio 49 0>;
		amzn,mic-downmix;
		pinctrl-names = "default",
				"audpmicclk-mode0",
				"audpmicclk-mode1",
				"audi2s1-mode0",
				"audi2s1-mode1",
				"extamp-pullhigh",
				"extamp-pulllow",
				"audmic-en",
				"i2s-mclk";
		pinctrl-0 = <&spi_pins_default>;
		pinctrl-1 = <&aud_pins_pmicclk_mode0>;
		pinctrl-2 = <&aud_pins_pmicclk_mode1>;
		pinctrl-3 = <&aud_pins_i2s1_mode0>;
		pinctrl-4 = <&aud_pins_i2s1_mode1>;
		pinctrl-5 = <&aud_pins_extamp_high>;
		pinctrl-6 = <&aud_pins_extamp_low>;
		pinctrl-7 = <&aud_pins_mic_en>;
		pinctrl-8 = <&aud_adc_mclk>;
		status = "okay";
	};
};

&tboard_thermistor{
	io-channels = <&auxadc 0>, <&auxadc 12>, <&auxadc 13>;
};

&touch {
	vtouch-supply = <&mt6323_vgp2_reg>;
	tpd-resolution = <720 1280>;
	use-tpd-button = <0>;
	tpd-key-num = <4>;
	tpd-key-local= <139 172 158 0>;
	tpd-key-dim-local = <60 850 50 30 180 850 50 30 300 850 50 30 420 850 50 30>;
	tpd-max-touch-num = <5>;
	tpd-filter-enable = <1>;
	tpd-filter-pixel-density = <124>;
	tpd-filter-custom-prameters = <0 0 0 0 0 0 0 0 0 0 0 0>;
	tpd-filter-custom-speed = <0 0 0>;
	pinctrl-names = "default", "state_eint_as_int", "state_eint_output0", "state_eint_output1",
		"state_rst_output0", "state_rst_output1";
	pinctrl-0 = <&CTP_pins_default>;
	pinctrl-1 = <&CTP_pins_eint_as_int>;
	pinctrl-2 = <&CTP_pins_eint_output0>;
	pinctrl-3 = <&CTP_pins_eint_output1>;
	pinctrl-4 = <&CTP_pins_rst_output0>;
	pinctrl-5 = <&CTP_pins_rst_output1>;
	status = "okay"; 
};

&uart0 {
	status="okay";
};

&usb0 {
	vusb-supply = <&mt6323_vusb_reg>;
	pinctrl-names = "iddig_irq_init", "iddig_irq_low", "iddig_irq_high";
	pinctrl-0 = <&gpio38_mode0_iddig>;
	pinctrl-1 = <&gpio38_mode0_iddig_low>;
	pinctrl-2 = <&gpio38_mode0_iddig_high>;
	iddig_gpio = <&pio 38 0>;
	status = "okay";
};

&spi_pads {
	   drive-strength = <MTK_DRIVE_6mA>;
	   input-schmitt-enable;
};

/delete-node/ &mdump_reserved_memory;

#include "checkers_thermal_zones.dtsi"
